# G32F031 register map
File version: 1.0
CPU: CM0PLUS r0p1, little endian, no MPU, no FPU, 2 interrupt priority bits
Registers are 32-bit, read-write, reset 0x0 unless marked. A register's access mark holds for its fields unless they carry their own. Offsets are from the block's base; [hi:lo] are bit positions; {n}, {i} and the like mark numbered series.

## RCC — Reset and clock control
Base 0x40020400
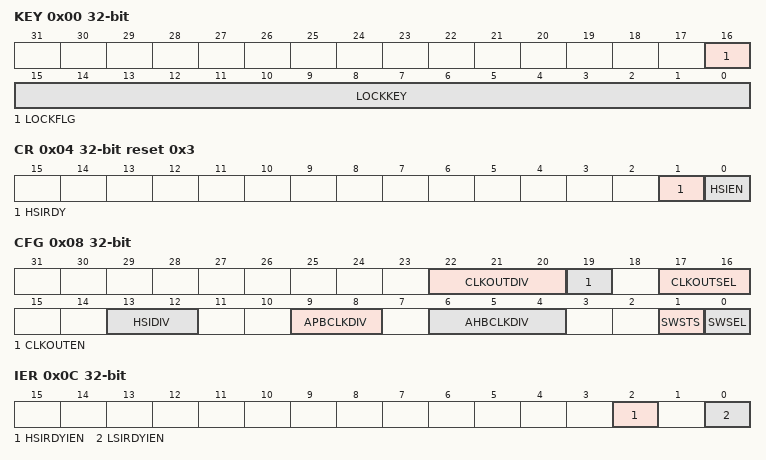
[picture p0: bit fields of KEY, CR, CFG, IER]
0x00 KEY access per field — RCC KEY register
  [16] LOCKFLG ro — Register Write Protection Flag
  [15:0] LOCKKEY wo — Password protection configuration for write operations
0x04 CR access per field reset 0x3 — RCC control register
  [1] HSIRDY ro — HSI clock stabilization flag
  [0] HSIEN rw — HSI clock enable
0x08 CFG access per field — RCC configuration register
  [22:20] CLKOUTDIV rw — Clock output division
  [19] CLKOUTEN rw — Clock output enable
  [17:16] CLKOUTSEL rw — Clock output select
  [13:12] HSIDIV rw — System clock HSI branch division
  [9:8] APBCLKDIV rw — APB clock division
  [6:4] AHBCLKDIV rw — AHB clock division
  [1] SWSTS ro — System clock select flag
  [0] SWSEL rw — System clock select
0x0C IER — RCC Interrupt Enable Register
  [2] HSIRDYIEN — HSI clock stabilization interrupt enable
  [0] LSIRDYIEN — LSI clock stabilization interrupt enable
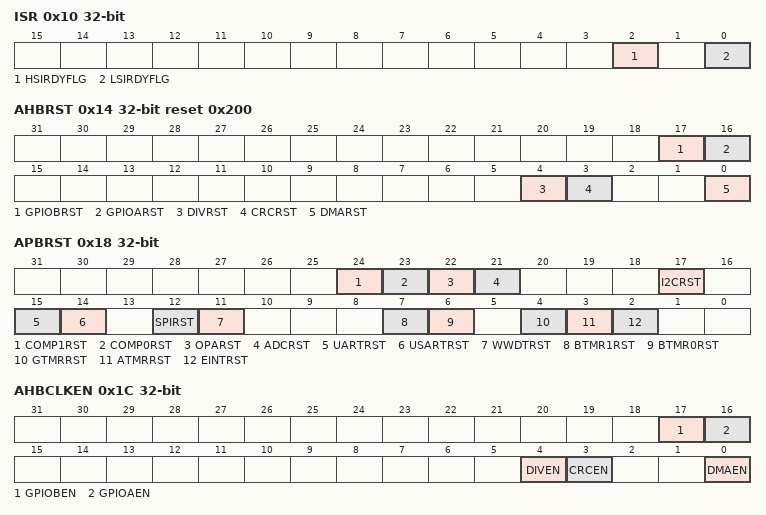
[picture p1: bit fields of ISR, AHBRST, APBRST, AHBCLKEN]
0x10 ISR — RCC Interrupt Flag Status Register
  [2] HSIRDYFLG — HSI clock stabilization interrupt flag
  [0] LSIRDYFLG — LSI clock stabilization interrupt flag
0x14 AHBRST reset 0x200 — RCC AHB Clock Reset Register
  [17] GPIOBRST — GPIOB reset
  [16] GPIOARST — GPIOA reset
  [4] DIVRST — DIV shift reset
  [3] CRCRST — CRC reset
  [0] DMARST — DMA reset
0x18 APBRST — RCC APB Clock Reset Register
  [24] COMP1RST — COMP1 reset
  [23] COMP0RST — COMP0 reset
  [22] OPARST — OPA reset
  [21] ADCRST — ADC reset
  [17] I2CRST — I2C reset
  [15] UARTRST — UART reset
  [14] USARTRST — USART reset
  [12] SPIRST — SPI reset
  [11] WWDTRST — WWDT reset
  [7] BTMR1RST — BTMR1 reset
  [6] BTMR0RST — BTMR0 reset
  [4] GTMRRST — GTMR reset
  [3] ATMRRST — ATMR reset
  [2] EINTRST — EINT reset
0x1C AHBCLKEN — RCC AHB Clock Enable Register
  [17] GPIOBEN — GPIOB clock enable
  [16] GPIOAEN — GPIOA clock enable
  [4] DIVEN — DIV SHIFT clock enable
  [3] CRCEN — CRC clock enable
  [0] DMAEN — DMA clock enable
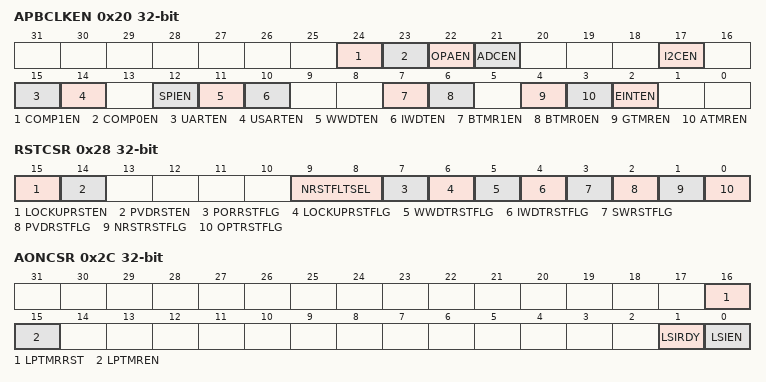
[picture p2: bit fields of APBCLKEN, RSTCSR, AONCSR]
0x20 APBCLKEN — RCC APB Clock Enable Register
  [24] COMP1EN — COMP1 enable
  [23] COMP0EN — COMP0 enable
  [22] OPAEN — OPA enable
  [21] ADCEN — ADC enable
  [17] I2CEN — I2C enable
  [15] UARTEN — UART enable
  [14] USARTEN — USART enable
  [12] SPIEN — SPI enable
  [11] WWDTEN — WWDT enable
  [10] IWDTEN — IWDT enable
  [7] BTMR1EN — BTMR1 enable
  [6] BTMR0EN — BTMR0 enable
  [4] GTMREN — GTMR enable
  [3] ATMREN — ATMR enable
  [2] EINTEN — EINT enable
0x24 ADCCR — RCC ADC Clock Control Register
  [1:0] ADCCLKDIV — ADC clock division
0x28 RSTCSR — RCC Reset Control and Status Register
  [15] LOCKUPRSTEN — LOCKUP system reset enable
  [14] PVDRSTEN — PVD system reset enable
  [9:8] NRSTFLTSEL — NRST filter select
  [7] PORRSTFLG — POR/PDR reset flag
  [6] LOCKUPRSTFLG — LOCKUP system reset flag
  [5] WWDTRSTFLG — WWDT system reset flag
  [4] IWDTRSTFLG — IWDT system reset flag
  [3] SWRSTFLG — Soft system reset flag
  [2] PVDRSTFLG — PVD system reset flag
  [1] NRSTRSTFLG — NRST reset flag
  [0] OPTRSTFLG — OB reload system reset flag
0x2C AONCSR access per field — AON Control Register
  [16] LPTMRRST rw — LPTMR reset
  [15] LPTMREN rw — LPTMR clock enable
  [1] LSIRDY ro — LSI clock ready flag
  [0] LSIEN rw — LSI clock enable

## FLASH — Flash memory controller
Base 0x40020800
0x00 WKEY — /
  [0] WKEY — Status 1: Unlocked. Status 0: Locked
0x04 MKEY — /
  [0] MKEY — Status 1: Unlocked. Status 0: Locked
0x0C NVRCKEY — /
  [0] NVRCKEY — Status 1: Unlocked. Status 0: Locked
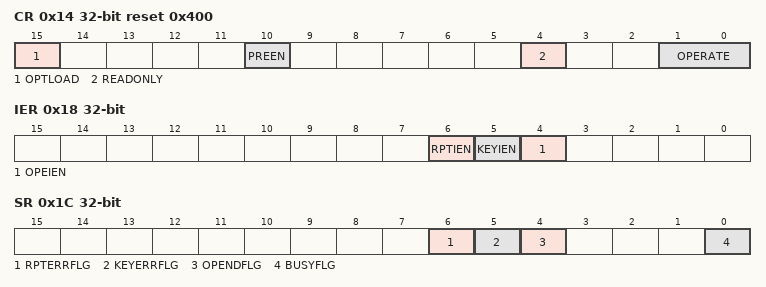
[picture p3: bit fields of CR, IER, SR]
0x14 CR reset 0x400 — /
  [15] OPTLOAD — The option byte is forcibly updated. When the data written to the high 16 bits is 0xa5a5 at the same time, the bit can be written as 1. When it is written as 1, the bit forcibly reloads the option byte, which will trigger a system reset. 0: Invalid 1: Valid
  [10] PREEN — Pre fetch enable.
  [4] READONLY — Flash ip read-only control, cannot be erased/written.
  [1:0] OPERATE — Flash operation type configuration
0x18 IER — /
  [6] RPTIEN — Flash Read/Write Protection Interrupt Enable
  [5] KEYIEN — Flash KEY Error Interrupt Enable
  [4] OPEIEN — Flash Erase End Interrupt Enable
0x1C SR access per field — /
  [6] RPTERRFLG rw — FLASH read and write protection error interrupt
  [5] KEYERRFLG rw — Flash KEY error interrupt, not unlocking flash erase.
  [4] OPENDFLG rw — FLASH erase finish interrupt
  [0] BUSYFLG ro — FLASH erase BUSY bit
0x20 CR1 reset 0x3 — /
  [1:0] LATENCY — The default value for the delay period on power-up at 64mhz (48mhz) is 2.

## CRC — Cryptographic processor
Base 0x40020C00
0x00 DR — Data register
  [31:0] DATA — As an input register: stores new data for the CRC calculator when writing; As an output register: returns the result of the CRC calculation when reading.
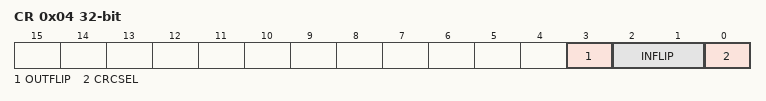
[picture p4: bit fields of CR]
0x04 CR — Control Register
  [3] OUTFLIP — Flip or not flip
  [2:1] INFLIP — Flip the input data in different units: do not flip, flip by byte, flip by half-word, flip by word.
  [0] CRCSEL — 32-bit, 16-bit CRC selection
0x08 INIT — Initial value data register
  [31:0] INIT — Setting the initial value of CRC.

## DIV
Base 0x40021000
0x00 DVDR — Dividend register
  [31:0] DIVIDEND
0x04 DVSR reset 0x1 — Divisor Register
  [31:0] DIVISOR
0x08 QUOTR wo — Quotient register
  [31:0] QUOTIENT
0x0C RMDR — Remainder register
  [31:0] REMAINDER
0x10 SR — Stauts register
  [0] OVF — Divide by zero overflow status flag
0x14 CR reset 0x1 — Control register
  [0] USIGNEN — Unsigned enable

## GPIOA — General-purpose I/Os
Base 0x48000000
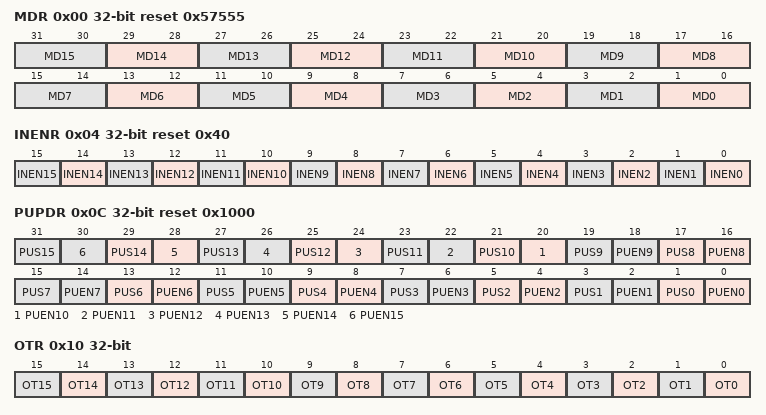
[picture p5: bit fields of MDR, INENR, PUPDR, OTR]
0x00 MDR reset 0x57555
  [2n+1:2n] MD{n} (n=0..15) — /
0x04 INENR reset 0x40
  [n] INEN{n} (n=0..15) — /
0x0C PUPDR reset 0x1000
  [2n+1] PUS{n} (n=0..15) — /
  [2n] PUEN{n} (n=0..15) — /
0x10 OTR
  [n] OT{n} (n=0..15) — /
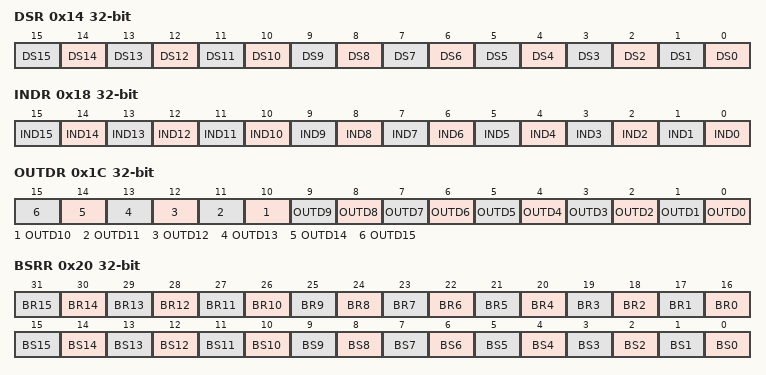
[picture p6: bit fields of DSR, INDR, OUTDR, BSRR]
0x14 DSR
  [n] DS{n} (n=0..15) — /
0x18 INDR ro
  [n] IND{n} (n=0..15) — /
0x1C OUTDR
  [n] OUTD{n} (n=0..15) — /
0x20 BSRR
  [n+16] BR{n} (n=0..15) — /
  [n] BS{n} (n=0..15) — /
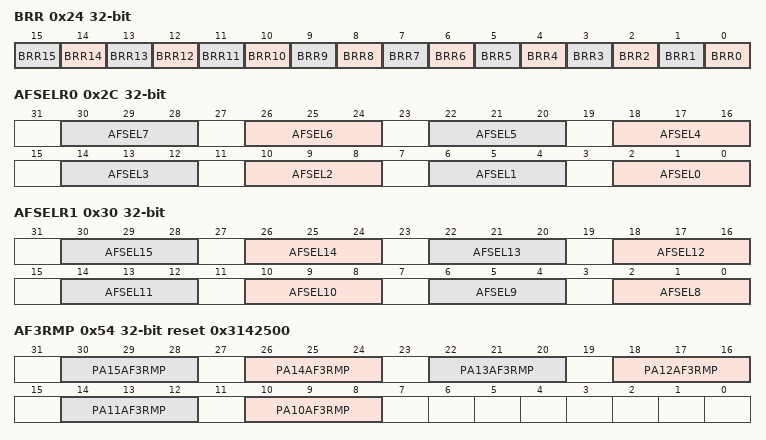
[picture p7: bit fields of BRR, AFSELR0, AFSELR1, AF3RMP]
0x24 BRR
  [n] BRR{n} (n=0..15) — /
0x28 LOCK
  [31:0] KEY — /
0x2C AFSELR0
  [4n+2:4n] AFSEL{n} (n=0..7) — /
0x30 AFSELR1
  [4n-30:4n-32] AFSEL{n} (n=8..15) — /
0x54 AF3RMP reset 0x3142500
  [4n-30:4n-32] PA{n}AF3RMP (n=10..15) — /

## GPIOB — General-purpose I/Os
Base 0x48000400
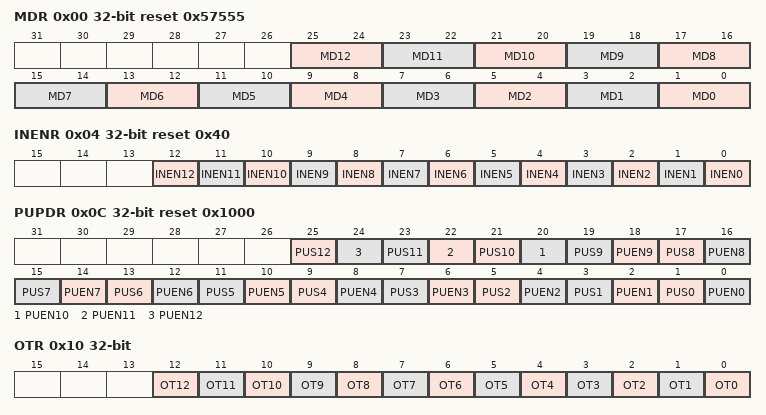
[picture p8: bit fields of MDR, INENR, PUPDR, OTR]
0x00 MDR reset 0x57555
  [2n+1:2n] MD{n} (n=0..12) — /
0x04 INENR reset 0x40
  [n] INEN{n} (n=0..12) — /
0x0C PUPDR reset 0x1000
  [2n+1] PUS{n} (n=0..12) — /
  [2n] PUEN{n} (n=0..12) — /
0x10 OTR
  [n] OT{n} (n=0..12) — /
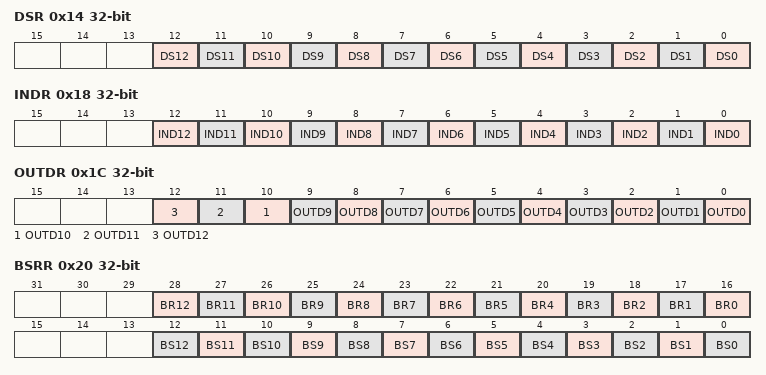
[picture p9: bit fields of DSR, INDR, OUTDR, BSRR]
0x14 DSR
  [n] DS{n} (n=0..12) — /
0x18 INDR
  [n] IND{n} (n=0..12) — /
0x1C OUTDR
  [n] OUTD{n} (n=0..12) — /
0x20 BSRR
  [n+16] BR{n} (n=0..12) — /
  [n] BS{n} (n=0..12) — /
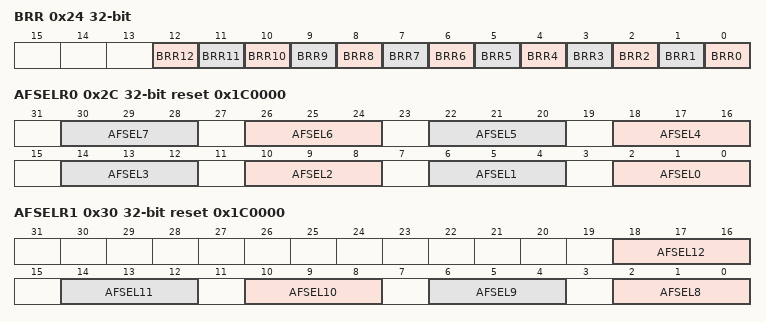
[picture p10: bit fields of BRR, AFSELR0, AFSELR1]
0x24 BRR
  [n] BRR{n} (n=0..12) — /
0x28 LOCK
  [31:0] KEY — /
0x2C AFSELR0 reset 0x1C0000
  [4n+2:4n] AFSEL{n} (n=0..7) — /
0x30 AFSELR1 reset 0x1C0000
  [4n-30:4n-32] AFSEL{n} (n=8..12) — /

## OPA
Base 0x40005800
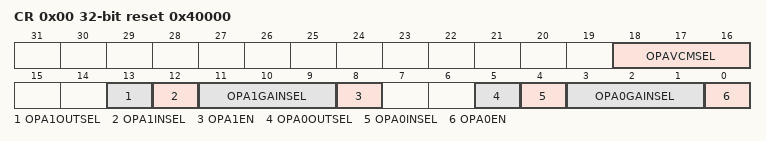
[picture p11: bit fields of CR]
0x00 CR reset 0x40000 — Control register
  [18:16] OPAVCMSEL — OPA VCM Selection
  [13] OPA1OUTSEL — OPA1 Output Selection
  [12] OPA1INSEL — OPA1 Input Selection
  [11:9] OPA1GAINSEL — OPA1 Gain Selection
  [8] OPA1EN — OPA1 Enable
  [5] OPA0OUTSEL — OPA0 Output Selection
  [4] OPA0INSEL — OPA0 Input Selection
  [3:1] OPA0GAINSEL — OPA0 Gain Selection
  [0] OPA0EN — OPA0 Enable
